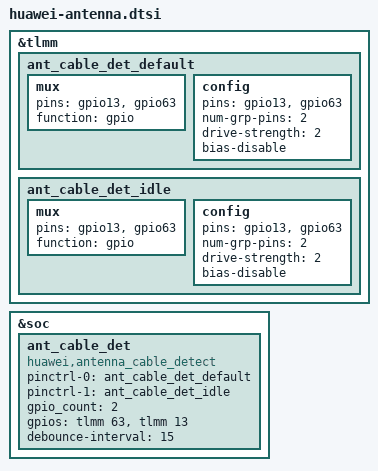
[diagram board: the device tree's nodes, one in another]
/* Copyright (c) 2014-2015, The Linux Foundation. All rights reserved.
 *
 * This program is free software; you can redistribute it and/or modify
 * it under the terms of the GNU General Public License version 2 and
 * only version 2 as published by the Free Software Foundation.
 *
 * This program is distributed in the hope that it will be useful,
 * but WITHOUT ANY WARRANTY; without even the implied warranty of
 * MERCHANTABILITY or FITNESS FOR A PARTICULAR PURPOSE.  See the
 * GNU General Public License for more details.
 */
&tlmm {
	ant_cable_det_default:ant_cable_det_default {
			mux {
				pins = "gpio13", "gpio63";
				function =  "gpio";
			};
			config {
				pins = "gpio13", "gpio63";
				num-grp-pins = <2>;
				drive-strength = <2>;
				bias-disable;
			};
	};
	ant_cable_det_idle:ant_cable_det_idle {
			mux {
				pins = "gpio13", "gpio63";
				function =  "gpio";
			};
			config {
				pins = "gpio13", "gpio63";
				num-grp-pins = <2>;
				drive-strength = <2>;
				bias-disable;
			};
	};
};

&soc {
	ant_cable_det {
		compatible = "huawei,antenna_cable_detect";
		pinctrl-names = "default", "idle";
		pinctrl-0 = <&ant_cable_det_default>;
		pinctrl-1 = <&ant_cable_det_idle>;
		gpio_count = <2>;
		gpios = <&tlmm 63 0>,<&tlmm 13 0>;
		debounce-interval = <15>;
	};
};
